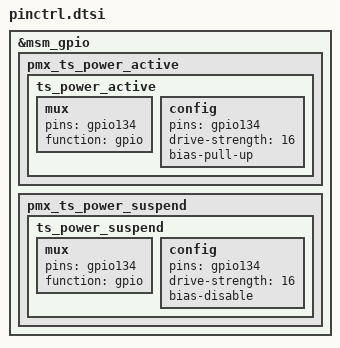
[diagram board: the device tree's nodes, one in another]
/*
 * Copyright (c) 2015, The Linux Foundation. All rights reserved.
 * Copyright (c) 2023, Irawans Prjkt. All rights reserved.
 *
 * This program is free software; you can redistribute it and/or modify
 * it under the terms of the GNU General Public License version 2 and
 * only version 2 as published by the Free Software Foundation.
 *
 * This program is distributed in the hope that it will be useful,
 * but WITHOUT ANY WARRANTY; without even the implied warranty of
 * MERCHANTABILITY or FITNESS FOR A PARTICULAR PURPOSE.  See the
 * GNU General Public License for more details.
 */

&msm_gpio {
    pmx_ts_power_active {
		ts_power_active: ts_power_active {
			mux {
				pins = "gpio134";
				function = "gpio";
			};

			config {
				pins = "gpio134";
				drive-strength = <16>;
				bias-pull-up;
			};
		};
	};

    pmx_ts_power_suspend {
		ts_power_suspend: ts_power_suspend {
			mux {
				pins = "gpio134";
				function = "gpio";
			};

			config {
				pins = "gpio134";
				drive-strength = <16>;
				bias-disable;
			};
		};
	};
};
